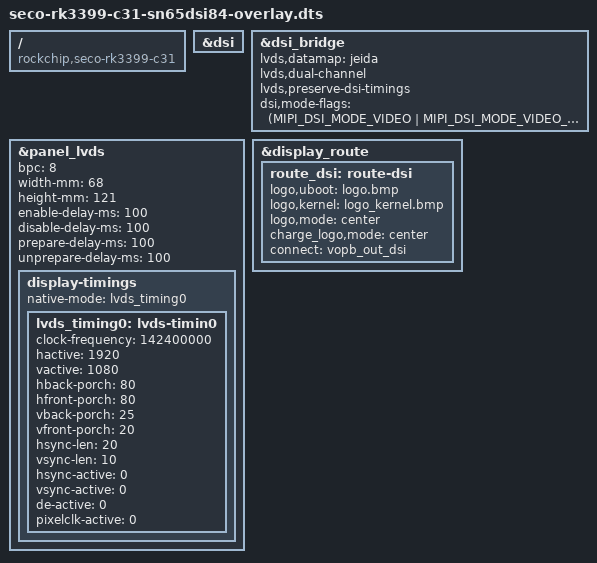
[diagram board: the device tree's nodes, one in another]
/*
 * Copyright 2020 SECO
 *
 * This program is free software; you can redistribute it and/or
 * modify it under the terms of the GNU General Public License
 * as published by the Free Software Foundation; either version 2
 * of the License, or (at your option) any later version.
 *
 * This program is distributed in the hope that it will be useful,
 * but WITHOUT ANY WARRANTY; without even the implied warranty of
 * MERCHANTABILITY or FITNESS FOR A PARTICULAR PURPOSE.  See the
 * GNU General Public License for more details.
 */

/dts-v1/;
/plugin/;

#include <dt-bindings/display/drm_mipi_dsi.h>

/ {
	compatible = "rockchip,seco-rk3399-c31", "rockchip,rk3399";  

/*  __________________________________________________________________________
 * |                                                                          |
 * |                               SN65DSI84	                              |
 * |__________________________________________________________________________|
 */


    	fragment@0 {
        	target = <&dsi>;
        	__overlay__ {
			status = "okay";
		};
	};

    	fragment@1 {
        	target = <&dsi_bridge>;
        	__overlay__ {
			status = "okay";
			lvds,datamap  = "jeida";
			lvds,dual-channel;
			lvds,preserve-dsi-timings;

			dsi,mode-flags = <(MIPI_DSI_MODE_VIDEO | MIPI_DSI_MODE_VIDEO_BURST | MIPI_DSI_MODE_LPM | MIPI_DSI_MODE_EOT_PACKET)>;
		};
	};

    	fragment@2 {
        	target = <&panel_lvds>;
        	__overlay__ {
			status = "okay";

			bpc                = <8>;
			width-mm           = <68>;
			height-mm          = <121>;

			enable-delay-ms    = <100>;
			disable-delay-ms   = <100>;
			prepare-delay-ms   = <100>;
			unprepare-delay-ms = <100>;

			display-timings {
				native-mode = <&lvds_timing0>;

				lvds_timing0: lvds-timin0 {
					clock-frequency = <142400000>;
					hactive         = <1920>;
					vactive         = <1080>;
					hback-porch     = <80>;
					hfront-porch    = <80>;
					vback-porch     = <25>;
					vfront-porch    = <20>;
					hsync-len       = <20>;
					vsync-len       = <10>;
					hsync-active    = <0>;
					vsync-active    = <0>;
					de-active       = <0>;
					pixelclk-active = <0>;
				};
			};

		};
	};

    	fragment@3 {
        	target = <&display_route>;
        	__overlay__ {
			route_dsi: route-dsi {
				status = "okay";
				logo,uboot = "logo.bmp";
				logo,kernel = "logo_kernel.bmp";
				logo,mode = "center";
				charge_logo,mode = "center";
				connect = <&vopb_out_dsi>;
			};
		};
	};
};

